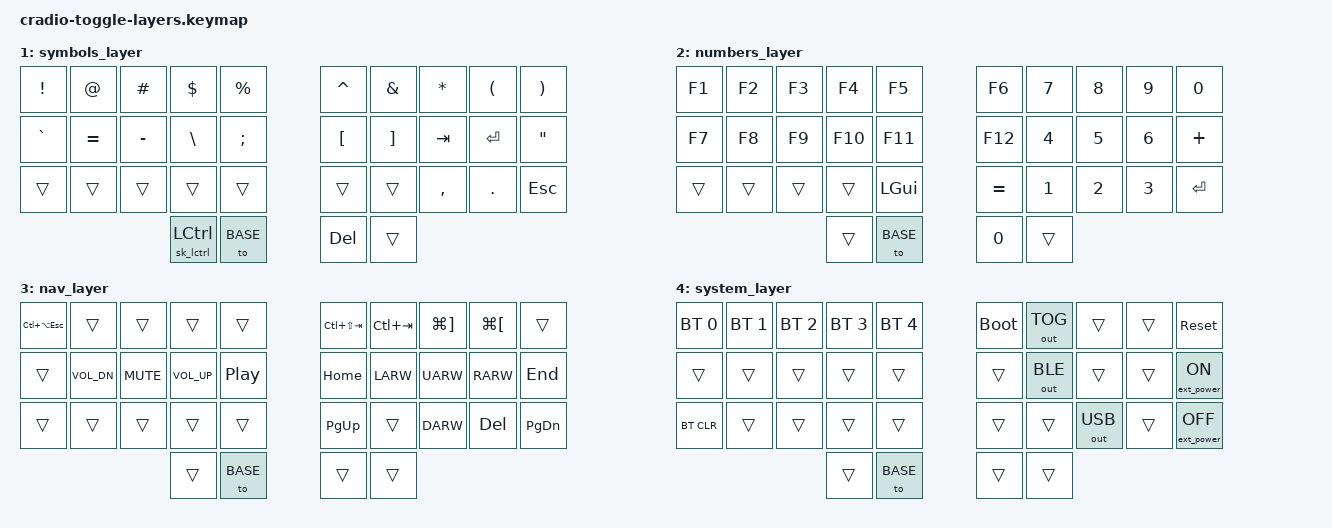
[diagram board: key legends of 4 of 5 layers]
// Copyright (c) 2022 The ZMK Contributors
// SPDX-License-Identifier: MIT
//
// OPTION 3: FULL TOGGLE LAYER SYSTEM (Ben Vallack Style)
// - Complete toggle-based layer switching
// - Progressive layer access (tap → symbols, double tap → numbers)
// - Universal return (left thumb always → home)
// - Selective HRM (only CMD/ALT on home row)
// - Sticky SHIFT/CTRL on thumbs
// - Panic mode for layer recovery

#include <behaviors/num_word.dtsi>
#include <behaviors.dtsi>
#include <dt-bindings/zmk/keys.h>
#include <dt-bindings/zmk/bt.h>
#include <dt-bindings/zmk/outputs.h>
#include <dt-bindings/zmk/ext_power.h>

// ---------- Layer indexes ----------
#define BASE     0 
#define SYMBOLS  1  // Renamed from NUMSYM for clarity
#define NUMBERS  2  // New dedicated numbers layer
#define NAV      3  // Navigation and arrows
#define SYSTEM   4

// ---------- Selective Home-row Mods (CMD/ALT only) ----------
#define HRML_LITE(k1,k2,k3,k4) &kp k1  &ht_slow LALT k2   &kp k3   &ht_slow LGUI k4
#define HRMR_LITE(k1,k2,k3,k4) &ht_slow RGUI k1   &kp k2  &ht_slow RALT k3    &kp k4

/ {
    behaviors {
        // Slow hold-tap for home row mods to prevent roll interference
        ht_slow: hold_tap_slow {
            compatible = "zmk,behavior-hold-tap";
            #binding-cells = <2>;
            flavor = "tap-preferred";
            tapping-term-ms = <300>;  // Long delay prevents accidental activation
            quick-tap-ms = <100>;
            require-prior-idle-ms = <150>;
            bindings = <&kp>, <&kp>;
        };

        // Sticky modifiers - tap for next key, hold for continuous
        sk_lshft: sticky_shift {
            compatible = "zmk,behavior-sticky-key";
            #binding-cells = <1>;
            bindings = <&kp>;
            release-after-ms = <1000>;
            quick-release;
        };

        sk_lctrl: sticky_ctrl {
            compatible = "zmk,behavior-sticky-key";
            #binding-cells = <1>;
            bindings = <&kp>;
            release-after-ms = <1000>;
            quick-release;
        };

        // Progressive layer access - Ben Vallack style
        td_layer_right: tap_dance_layer_right {
            compatible = "zmk,behavior-tap-dance";
            #binding-cells = <0>;
            tapping-term-ms = <200>;
            bindings = <&to SYMBOLS>, <&to NUMBERS>;
        };

        // Universal return to base layer
        return_base: return_to_base {
            compatible = "zmk,behavior-tap-dance";
            #binding-cells = <0>;
            tapping-term-ms = <200>;
            bindings = <&to BASE>, <&kp SPACE>;  // Tap for space, double tap ensures return
        };

        // Left thumb with MEH functionality (for app switching)
        meh_space: meh_or_space {
            compatible = "zmk,behavior-hold-tap";
            #binding-cells = <2>;
            flavor = "tap-preferred";
            tapping-term-ms = <200>;
            quick-tap-ms = <120>;
            require-prior-idle-ms = <100>;
            bindings = <&kp>, <&return_base>;
        };
    };

    // ---------- Combos for enhanced functionality ----------
    combos {
        compatible = "zmk,combos";
        
        // Panic mode - double thumb tap returns to base from ANY layer
        combo_panic {
            timeout-ms = <50>;
            key-positions = <30 33>;
            bindings = <&to BASE>;
            layers = <BASE SYMBOLS NUMBERS NAV SYSTEM>;
        };

        // Essential shortcuts as combos
        combo_enter {
            timeout-ms = <40>;
            key-positions = <17 18 19>; // J K L
            bindings = <&kp ENTER>;
            layers = <BASE>;
        };

        combo_hyphen {
            timeout-ms = <40>;
            key-positions = <22 23>; // C V
            bindings = <&kp MINUS>;
            layers = <BASE>;
        };

        combo_tab {
            timeout-ms = <40>;
            key-positions = <12 13>; // D F
            bindings = <&kp TAB>;
            layers = <BASE>;
        };

        // Access to NAV layer from SYMBOLS
        combo_nav_access {
            timeout-ms = <40>;
            key-positions = <14 19>; // Pinky positions
            bindings = <&to NAV>;
            layers = <SYMBOLS>;
        };
    };

    // ---------- Conditional layers for system access ----------
    conditional_layers {
        compatible = "zmk,conditional-layers";
        system_layer {
            if-layers = <NUMBERS NAV>;
            then-layer = <SYSTEM>;
        };
    };

    keymap {
        compatible = "zmk,keymap";
        
        base_layer {
            bindings = <
        //╭──────────┬──────────┬──────────┬──────────┬──────────╮   ╭──────────┬──────────┬──────────┬──────────┬──────────╮
        //│  Q       │  W       │  E       │  R       │  T       │   │  Y       │  U       │  I       │  O       │  P       │
             &kp Q      &kp W      &kp E      &kp R      &kp T          &kp Y      &kp U      &kp I      &kp O      &kp P
        //├──────────┼──────────┼──────────┼──────────┼──────────┤   ├──────────┼──────────┼──────────┼──────────┼──────────┤
        //│  A       │  S       │  D       │  F       │  G       │   │  H       │  J       │  K       │  L       │ ' "      │
             HRML_LITE(A, S,       D,         F)         &kp G          &kp H      HRMR_LITE(J, K,       L,        SQT)
        //├──────────┼──────────┼──────────┼──────────┼──────────┤   ├──────────┼──────────┼──────────┼──────────┼──────────┤
        //│  Z       │  X       │  C       │  V       │  B       │   │  N       │  M       │ , <      │ . >      │ / ?      │
            &kp Z      &kp X      &kp C      &kp V      &kp B          &kp N      &kp M      &kp COMMA  &kp DOT    &kp FSLH
        //╰──────────┴──────────┴──────────┼──────────┼──────────┤   ├──────────┼──────────┼──────────┴──────────┴──────────╯
                              &sk_lshft LSHFT  &meh_space LS(LC(LA(LGUI))) 0   &kp BSPC  &td_layer_right
        //                                 ╰──────────┴──────────╯   ╰──────────┴──────────╯
            >;
        };

        symbols_layer {
            bindings = <
        //╭──────────┬──────────┬──────────┬──────────┬──────────╮   ╭──────────┬──────────┬──────────┬──────────┬──────────╮
        //│ !        │ @        │ #        │ $        │ %        │   │ ^        │ &        │ *        │ ( )      │ ) }      │
            &kp EXCL   &kp AT     &kp HASH   &kp DLLR   &kp PRCNT      &kp CARET  &kp AMPS   &kp STAR   &kp LPAR   &kp RPAR
        //├──────────┼──────────┼──────────┼──────────┼──────────┤   ├──────────┼──────────┼──────────┼──────────┼──────────┤
        //│ ` ~      │ = +      │ - _      │  \ |     │  ; :     │   │ [ {      │ ] }      │ TAB      │ ENTER    │  " '     │
            &kp GRAVE  &kp EQUAL  &kp MINUS  &kp BSLH   &kp SEMI       &kp LBKT   &kp RBKT   &kp TAB    &kp ENTER  &kp DQT
        //├──────────┼──────────┼──────────┼──────────┼──────────┤   ├──────────┼──────────┼──────────┼──────────┼──────────┤
        //│          │          │          │          │          │   │          │          │ , <      │ . >      │ ESC      │
            &trans     &trans     &trans     &trans     &trans         &trans     &trans     &kp COMMA  &kp DOT    &kp ESC
        //╰──────────┴──────────┴──────────┼──────────┼──────────┤   ├──────────┼──────────┼──────────┴──────────┴──────────╯
                                    &sk_lctrl LCTRL  &to BASE         &kp DEL    &trans
        //                                 ╰──────────┴──────────╯   ╰──────────┴──────────╯
            >;
        };

        numbers_layer {
            bindings = <
        //╭──────────┬──────────┬──────────┬──────────┬──────────╮   ╭──────────┬──────────┬──────────┬──────────┬──────────╮
        //│ F1       │ F2       │ F3       │ F4       │ F5       │   │ F6       │ 7        │ 8        │ 9        │  0       │
            &kp F1     &kp F2     &kp F3     &kp F4     &kp F5         &kp F6     &kp N7     &kp N8     &kp N9     &kp N0
        //├──────────┼──────────┼──────────┼──────────┼──────────┤   ├──────────┼──────────┼──────────┼──────────┼──────────┤
        //│ F7       │ F8       │ F9       │ F10      │ F11      │   │ F12      │ 4        │ 5        │ 6        │  +       │
            &kp F7     &kp F8     &kp F9     &kp F10    &kp F11        &kp F12    &kp N4     &kp N5     &kp N6     &kp PLUS
        //├──────────┼──────────┼──────────┼──────────┼──────────┤   ├──────────┼──────────┼──────────┼──────────┼──────────┤
        //│          │          │          │          │  CMD     │   │  =       │ 1        │ 2        │ 3        │  ENTER   │
            &trans     &trans     &trans     &trans     &kp LGUI       &kp EQUAL  &kp N1     &kp N2     &kp N3     &kp ENTER
        //╰──────────┴──────────┴──────────┼──────────┼──────────┤   ├──────────┼──────────┼──────────┴──────────┴──────────╯
                                             &trans     &to BASE       &kp N0     &trans
        //                                 ╰──────────┴──────────╯   ╰──────────┴──────────╯
            >;
        };

        nav_layer {
            bindings = <
        //╭──────────┬──────────┬──────────┬──────────┬──────────╮   ╭──────────┬──────────┬──────────┬──────────┬──────────╮
        //│ FORCE QT │          │          │          │          │   │ PREV TAB │ NEXT TAB │ FRWD     │ BKWD     │          │
        &kp LC(LA(ESC)) &trans   &trans     &trans     &trans         &kp LC(LS(TAB)) &kp LC(TAB) &kp LG(RBKT) &kp LG(LBKT) &trans
        //├──────────┼──────────┼──────────┼──────────┼──────────┤   ├──────────┼──────────┼──────────┼──────────┼──────────┤
        //│          │ VOL DN   │ MUTE     │ VOL UP   │ PLAY     │   │  HOME    │  LEFT    │  UP      │ RIGHT    │   END    │
            &trans  &kp C_VOL_DN &kp K_MUTE &kp C_VOL_UP &kp C_PP      &kp HOME   &kp LARW   &kp UARW   &kp RARW   &kp END
        //├──────────┼──────────┼──────────┼──────────┼──────────┤   ├──────────┼──────────┼──────────┼──────────┼──────────┤
        //│          │          │          │          │          │   │ PAGE_UP  │          │ DOWN     │   DEL    │ PAGE_DN  │
            &trans     &trans     &trans     &trans     &trans         &kp PG_UP  &trans     &kp DARW   &kp DEL    &kp PG_DN
        //╰──────────┴──────────┴──────────┼──────────┼──────────┤   ├──────────┼──────────┼──────────┴──────────┴──────────╯
                                             &trans     &to BASE       &trans     &trans
        //                                 ╰──────────┴──────────╯   ╰──────────┴──────────╯
            >;
        };

        system_layer {
            bindings = <
        //╭──────────┬──────────┬──────────┬──────────┬──────────╮   ╭──────────┬──────────┬──────────┬──────────┬──────────╮
        //│ PROFILE 0│ PROFILE 1│PROFILE 2 │PROFILE 3 │PROFILE 4 │   │BOOTLOADER│ OUT TOG  │          │          │  RESET   │
        &bt BT_SEL 0  &bt BT_SEL 1 &bt BT_SEL 2 &bt BT_SEL 3  &bt BT_SEL 4        &bootloader &out OUT_TOG &trans      &trans   &sys_reset
        //├──────────┼──────────┼──────────┼──────────┼──────────┤   ├──────────┼──────────┼──────────┼──────────┼──────────┤
        //│          │          │          │          │          │   │          │          │          │          │EP ON     │
           &trans      &trans     &trans     &trans    &trans          &trans &out OUT_BLE     &trans     &trans  &ext_power EP_ON
        //├──────────┼──────────┼──────────┼──────────┼──────────┤   ├──────────┼──────────┼──────────┼──────────┼──────────┤
        //│ CLEAR BT │          │          │          │	         │   │          │          │          │          │EP OFF    │
           &bt BT_CLR  &trans     &trans    &trans	&trans          &trans     &trans   &out OUT_USB  &trans  &ext_power EP_OFF
        //╰──────────┴──────────┴──────────┼──────────┼──────────┤   ├──────────┼──────────┼──────────┴──────────┴──────────╯
                                          &trans     &to BASE       &trans     &trans
        //                                 ╰──────────┴──────────╯   ╰──────────┴──────────╯
            >;
        };
    };
};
